# MSP430FR5739 register map
File version: 1.1
CPU: msp430
Registers are 16-bit, access not given, reset 0x0 unless marked. A register's access mark holds for its fields unless they carry their own. Offsets are from the block's base; [hi:lo] are bit positions; {n}, {i} and the like mark numbered series.

## Comparator_D
Base 0x00000000
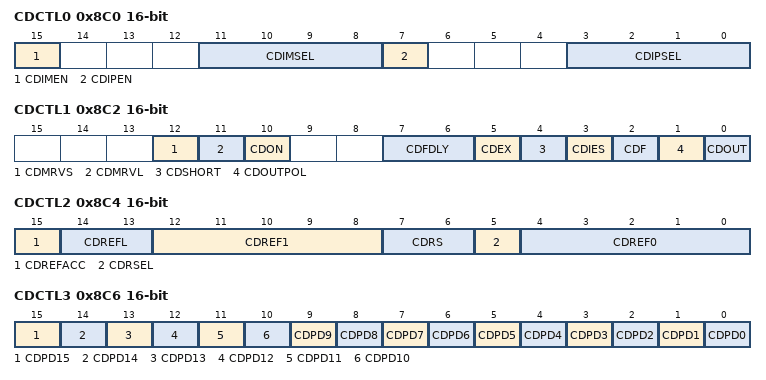
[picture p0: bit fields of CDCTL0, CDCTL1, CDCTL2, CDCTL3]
0x8C0 CDCTL0 — Comparator D Control Register 0
  [15] CDIMEN — [15:15] Comp. D Neg. Channel Input Enable
  [11:8] CDIMSEL — [11:8] Comp. D Neg. Channel Input Select 0
    {v}=Comp. D V- Terminal Input Select: Channel {v} (v=0..7); {v}=Comp. D V- terminal Input Select: Channel {v} (v=8..15)
  [7] CDIPEN — [7:7] Comp. D Pos. Channel Input Enable
  [3:0] CDIPSEL — [3:0] Comp. D Pos. Channel Input Select 0
    {v}=Comp. D V+ terminal Input Select: Channel {v} (v=0..15)
0x8C2 CDCTL1 — Comparator D Control Register 1
  [12] CDMRVS — [12:12] Comp. D Output selects between VREF0 or VREF1
  [11] CDMRVL — [11:11] Comp. D CDMRV Level
  [10] CDON — [10:10] Comp. D enable
  [7:6] CDFDLY — [7:6] Comp. D Filter delay Bit 0
    0=Comp. D Filter delay 0 : 450ns; 1=Comp. D Filter delay 1 : 900ns; 2=Comp. D Filter delay 2 : 1800ns; 3=Comp. D Filter delay 3 : 3600ns
  [5] CDEX — [5:5] Comp. D Exchange Inputs
  [4] CDSHORT — [4:4] Comp. D Input Short
  [3] CDIES — [3:3] Comp. D Interrupt Edge Select
  [2] CDF — [2:2] Comp. D Enable Output Filter
  [1] CDOUTPOL — [1:1] Comp. D Output Polarity
  [0] CDOUT — [0:0] Comp. D Output
0x8C4 CDCTL2 — Comparator D Control Register 2
  [15] CDREFACC — [15:15] Comp. D Reference Accuracy
  [14:13] CDREFL — [14:13] Comp. D Reference voltage level Bit : 0
    0=Comp. D Reference voltage level 0 : None; 1=Comp. D Reference voltage level 1 : 1.5V; 2=Comp. D Reference voltage level 2 : 2.0V; 3=Comp. D Reference voltage level 3 : 2.5V
  [12:8] CDREF1 — [12:8] Comp. D Reference 1 Resistor Select Bit : 0
    {v}=Comp. D Int. Ref.1 Select {v} : {v+1}/32 (v=0..7); {v}=Comp. D Int. Ref.1 Select {v-8} : {v+1}/32 (v=8..15); {v}=Comp. D Int. Ref.1 Select {v-16} : {v+1}/32 (v=16..23); {v}=Comp. D Int. Ref.1 Select {v-24} : {v+1}/32 (v=24..31)
  [7:6] CDRS — [7:6] Comp. D Reference Source Bit : 0
    0=Comp. D Reference Source 0 : Off; 1=Comp. D Reference Source 1 : Vcc; 2=Comp. D Reference Source 2 : Shared Ref.; 3=Comp. D Reference Source 3 : Shared Ref. / Off
  [5] CDRSEL — [5:5] Comp. D Reference select
  [4:0] CDREF0 — [4:0] Comp. D Reference 0 Resistor Select Bit : 0
    {v}=Comp. D Int. Ref.0 Select {v} : {v+1}/32 (v=0..7); {v}=Comp. D Int. Ref.0 Select {v-8} : {v+1}/32 (v=8..15); {v}=Comp. D Int. Ref.0 Select {v-16} : {v+1}/32 (v=16..23); {v}=Comp. D Int. Ref.0 Select {v-24} : {v+1}/32 (v=24..31)
0x8C6 CDCTL3 — Comparator D Control Register 3
  [15] CDPD15 — [15:15] Comp. D Disable Input Buffer of Port Register .15
  [14] CDPD14 — [14:14] Comp. D Disable Input Buffer of Port Register .14
  [13] CDPD13 — [13:13] Comp. D Disable Input Buffer of Port Register .13
  [12] CDPD12 — [12:12] Comp. D Disable Input Buffer of Port Register .12
  [11] CDPD11 — [11:11] Comp. D Disable Input Buffer of Port Register .11
  [10] CDPD10 — [10:10] Comp. D Disable Input Buffer of Port Register .10
  [9] CDPD9 — [9:9] Comp. D Disable Input Buffer of Port Register .9
  [8] CDPD8 — [8:8] Comp. D Disable Input Buffer of Port Register .8
  [7] CDPD7 — [7:7] Comp. D Disable Input Buffer of Port Register .7
  [6] CDPD6 — [6:6] Comp. D Disable Input Buffer of Port Register .6
  [5] CDPD5 — [5:5] Comp. D Disable Input Buffer of Port Register .5
  [4] CDPD4 — [4:4] Comp. D Disable Input Buffer of Port Register .4
  [3] CDPD3 — [3:3] Comp. D Disable Input Buffer of Port Register .3
  [2] CDPD2 — [2:2] Comp. D Disable Input Buffer of Port Register .2
  [1] CDPD1 — [1:1] Comp. D Disable Input Buffer of Port Register .1
  [0] CDPD0 — [0:0] Comp. D Disable Input Buffer of Port Register .0
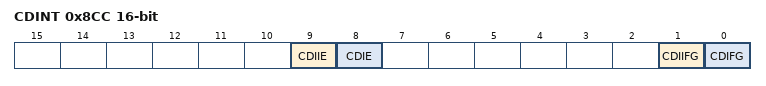
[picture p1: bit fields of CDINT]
0x8CC CDINT — Comparator D Interrupt Register
  [9] CDIIE — [9:9] Comp. D Interrupt Enable Inverted Polarity
  [8] CDIE — [8:8] Comp. D Interrupt Enable
  [1] CDIIFG — [1:1] Comp. D Interrupt Flag Inverted Polarity
  [0] CDIFG — [0:0] Comp. D Interrupt Flag
0x8CE CDIV — Comparator D Interrupt Vector Word
